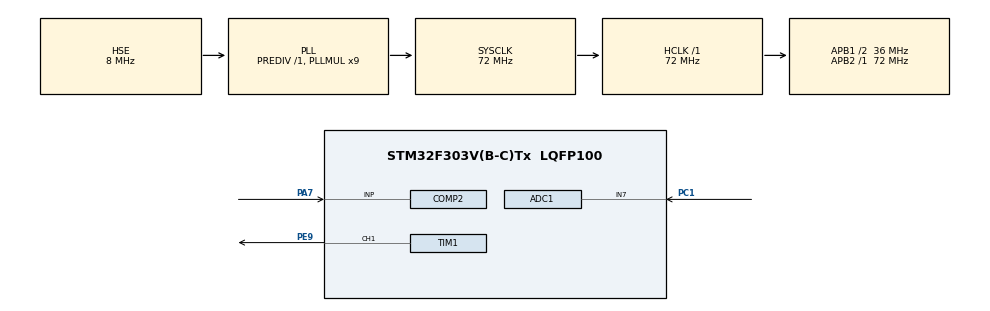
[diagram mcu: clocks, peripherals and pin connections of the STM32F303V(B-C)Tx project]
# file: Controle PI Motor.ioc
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ADC1.Channel-0\#ChannelRegularConversion=ADC_CHANNEL_7
ADC1.ContinuousConvMode=ENABLE
ADC1.DMAContinuousRequests=ENABLE
ADC1.NbrOfConversionFlag=1
ADC1.Offset-0\#ChannelRegularConversion=0
ADC1.OffsetNumber-0\#ChannelRegularConversion=ADC_OFFSET_NONE
ADC1.Rank-0\#ChannelRegularConversion=1
ADC1.SamplingTime-0\#ChannelRegularConversion=ADC_SAMPLETIME_601CYCLES_5
ADC1.master=1
COMP2.Hysteresis=COMP_HYSTERESIS_MEDIUM
COMP2.InvertingInput=COMP_INVERTINGINPUT_3_4VREFINT
COMP2.TriggerMode=COMP_TRIGGERMODE_IT_RISING
Dma.ADC1.0.Direction=DMA_PERIPH_TO_MEMORY
Dma.ADC1.0.Instance=DMA1_Channel1
Dma.ADC1.0.MemDataAlignment=DMA_MDATAALIGN_HALFWORD
Dma.ADC1.0.MemInc=DMA_MINC_ENABLE
Dma.ADC1.0.Mode=DMA_CIRCULAR
Dma.ADC1.0.PeriphDataAlignment=DMA_PDATAALIGN_HALFWORD
Dma.ADC1.0.PeriphInc=DMA_PINC_DISABLE
Dma.ADC1.0.Priority=DMA_PRIORITY_LOW
Dma.Request0=ADC1
Mcu.Family=STM32F3
Mcu.Name=STM32F303V(B-C)Tx
Mcu.Package=LQFP100
NVIC.COMP1_2_3_IRQn=true\:0\:0\:false\:false\:true\:false\:true\:true
NVIC.DMA1_Channel1_IRQn=true\:0\:0\:false\:false\:true\:false\:true\:true
NVIC.PVD_IRQn=true\:0\:0\:false\:false\:true\:true\:true\:true
NVIC.PriorityGroup=NVIC_PRIORITYGROUP_0
NVIC.TIM2_IRQn=true\:0\:0\:false\:false\:true\:true\:true\:true
PA13.Mode=Serial_Wire
PA13.Signal=SYS_JTMS-SWDIO
PA14.Mode=Serial_Wire
PA14.Signal=SYS_JTCK-SWCLK
PA7.Mode=INP
PA7.Signal=COMP2_INP
PC1.Signal=ADCx_IN7
PE9.Signal=S_TIM1_CH1
PF0-OSC_IN.Mode=HSE-External-Oscillator
PF0-OSC_IN.Signal=RCC_OSC_IN
PF1-OSC_OUT.Mode=HSE-External-Oscillator
PF1-OSC_OUT.Signal=RCC_OSC_OUT
ProjectManager.HeapSize=0x200
ProjectManager.StackSize=0x400
ProjectManager.TargetToolchain=STM32CubeIDE
RCC.AHBFreq_Value=72000000
RCC.APB1CLKDivider=RCC_HCLK_DIV2
RCC.APB1Freq_Value=36000000
RCC.APB1TimFreq_Value=72000000
RCC.APB2Freq_Value=72000000
RCC.APB2TimFreq_Value=72000000
RCC.CortexFreq_Value=72000000
RCC.HCLKFreq_Value=72000000
RCC.HSE_VALUE=8000000
RCC.HSI_VALUE=8000000
RCC.LSE_VALUE=32768
RCC.PLLMUL=RCC_PLL_MUL9
RCC.PLLSourceVirtual=RCC_PLLSOURCE_HSE
RCC.SYSCLKFreq_VALUE=72000000
RCC.SYSCLKSourceVirtual=RCC_SYSCLKSOURCE_PLLCLK
RCC.USBFreq_Value=72000000
SH.ADCx_IN7.0=ADC1_IN7,IN7-Single-Ended
SH.S_TIM1_CH1.0=TIM1_CH1,PWM Generation1 CH1
TIM1.Channel-PWM\ Generation1\ CH1=TIM_CHANNEL_1
TIM1.Period=100
TIM1.Prescaler=180-1
TIM2.AutoReloadPreload=TIM_AUTORELOAD_PRELOAD_ENABLE
TIM2.Period=1000-1
TIM2.Prescaler=72-1
VP_COMP2_VS_VREFINT34.Mode=VREFINT_34
VP_TIM2_VS_ClockSourceINT.Mode=Internal
board=STM32F3DISCOVERY

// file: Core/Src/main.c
/* USER CODE BEGIN Header */
/**
  ******************************************************************************
  * @file           : main.c
  * @brief          : Main program body
  ******************************************************************************
  * @attention
  *
  * Copyright (c) 2024 STMicroelectronics.
  * All rights reserved.
  *
  * This software is licensed under terms that can be found in the LICENSE file
  * in the root directory of this software component.
  * If no LICENSE file comes with this software, it is provided AS-IS.
  *
  ******************************************************************************
  */
/* USER CODE END Header */
#include "main.h"

ADC_HandleTypeDef hadc1;
DMA_HandleTypeDef hdma_adc1;

COMP_HandleTypeDef hcomp2;

TIM_HandleTypeDef htim1;
TIM_HandleTypeDef htim2;

/* USER CODE BEGIN PV */
uint32_t leitura, duty, count;
float u[2], ref=0, vel=0, e[2];
int k=1;
float u_max, u_min;
/* USER CODE END PV */

void SystemClock_Config(void);
static void MX_GPIO_Init(void);
static void MX_DMA_Init(void);
static void MX_ADC1_Init(void);
static void MX_TIM1_Init(void);
static void MX_TIM2_Init(void);
static void MX_COMP2_Init(void);

int main(void)
{

  /* MCU Configuration--------------------------------------------------------*/

  /* Reset of all peripherals, Initializes the Flash interface and the Systick. */
  HAL_Init();

  /* Configure the system clock */
  SystemClock_Config();

  /* Initialize all configured peripherals */
  MX_GPIO_Init();
  MX_DMA_Init();
  MX_ADC1_Init();
  MX_TIM1_Init();
  MX_TIM2_Init();
  MX_COMP2_Init();
  /* USER CODE BEGIN 2 */
  HAL_ADC_Start_DMA(&hadc1, &leitura, 1);
  HAL_TIM_PWM_Start(&htim1, TIM_CHANNEL_1);
  HAL_TIM_Base_Start_IT(&htim2);
  HAL_COMP_Start_IT(&hcomp2);

  u[0]=0;
  u[1]=0;
  e[0]=0;
  e[1]=0;
  /* USER CODE END 2 */

  /* Infinite loop */
  while (1)
  {

    /* USER CODE BEGIN 3 */
	  //HAL_GPIO_TogglePin(GPIOE, GPIO_PIN_10);
	  //HAL_Delay(1000);
  }
  /* USER CODE END 3 */
}

void SystemClock_Config(void)
{
  RCC_OscInitTypeDef RCC_OscInitStruct = {0};
  RCC_ClkInitTypeDef RCC_ClkInitStruct = {0};
  RCC_PeriphCLKInitTypeDef PeriphClkInit = {0};

  /** Initializes the RCC Oscillators according to the specified parameters
  * in the RCC_OscInitTypeDef structure.
  */
  RCC_OscInitStruct.OscillatorType = RCC_OSCILLATORTYPE_HSE;
  RCC_OscInitStruct.HSEState = RCC_HSE_ON;
  RCC_OscInitStruct.HSEPredivValue = RCC_HSE_PREDIV_DIV1;
  RCC_OscInitStruct.HSIState = RCC_HSI_ON;
  RCC_OscInitStruct.PLL.PLLState = RCC_PLL_ON;
  RCC_OscInitStruct.PLL.PLLSource = RCC_PLLSOURCE_HSE;
  RCC_OscInitStruct.PLL.PLLMUL = RCC_PLL_MUL9;
  if (HAL_RCC_OscConfig(&RCC_OscInitStruct) != HAL_OK)
  {
    Error_Handler();
  }

  /** Initializes the CPU, AHB and APB buses clocks
  */
  RCC_ClkInitStruct.ClockType = RCC_CLOCKTYPE_HCLK|RCC_CLOCKTYPE_SYSCLK
                              |RCC_CLOCKTYPE_PCLK1|RCC_CLOCKTYPE_PCLK2;
  RCC_ClkInitStruct.SYSCLKSource = RCC_SYSCLKSOURCE_PLLCLK;
  RCC_ClkInitStruct.AHBCLKDivider = RCC_SYSCLK_DIV1;
  RCC_ClkInitStruct.APB1CLKDivider = RCC_HCLK_DIV2;
  RCC_ClkInitStruct.APB2CLKDivider = RCC_HCLK_DIV1;

  if (HAL_RCC_ClockConfig(&RCC_ClkInitStruct, FLASH_LATENCY_2) != HAL_OK)
  {
    Error_Handler();
  }
  PeriphClkInit.PeriphClockSelection = RCC_PERIPHCLK_TIM1|RCC_PERIPHCLK_ADC12;
  PeriphClkInit.Adc12ClockSelection = RCC_ADC12PLLCLK_DIV1;
  PeriphClkInit.Tim1ClockSelection = RCC_TIM1CLK_HCLK;
  if (HAL_RCCEx_PeriphCLKConfig(&PeriphClkInit) != HAL_OK)
  {
    Error_Handler();
  }
}

static void MX_ADC1_Init(void)
{

  ADC_MultiModeTypeDef multimode = {0};
  ADC_ChannelConfTypeDef sConfig = {0};

  /** Common config
  */
  hadc1.Instance = ADC1;
  hadc1.Init.ClockPrescaler = ADC_CLOCK_ASYNC_DIV1;
  hadc1.Init.Resolution = ADC_RESOLUTION_12B;
  hadc1.Init.ScanConvMode = ADC_SCAN_DISABLE;
  hadc1.Init.ContinuousConvMode = ENABLE;
  hadc1.Init.DiscontinuousConvMode = DISABLE;
  hadc1.Init.ExternalTrigConvEdge = ADC_EXTERNALTRIGCONVEDGE_NONE;
  hadc1.Init.ExternalTrigConv = ADC_SOFTWARE_START;
  hadc1.Init.DataAlign = ADC_DATAALIGN_RIGHT;
  hadc1.Init.NbrOfConversion = 1;
  hadc1.Init.DMAContinuousRequests = ENABLE;
  hadc1.Init.EOCSelection = ADC_EOC_SINGLE_CONV;
  hadc1.Init.LowPowerAutoWait = DISABLE;
  hadc1.Init.Overrun = ADC_OVR_DATA_OVERWRITTEN;
  if (HAL_ADC_Init(&hadc1) != HAL_OK)
  {
    Error_Handler();
  }

  /** Configure the ADC multi-mode
  */
  multimode.Mode = ADC_MODE_INDEPENDENT;
  if (HAL_ADCEx_MultiModeConfigChannel(&hadc1, &multimode) != HAL_OK)
  {
    Error_Handler();
  }

  /** Configure Regular Channel
  */
  sConfig.Channel = ADC_CHANNEL_7;
  sConfig.Rank = ADC_REGULAR_RANK_1;
  sConfig.SingleDiff = ADC_SINGLE_ENDED;
  sConfig.SamplingTime = ADC_SAMPLETIME_601CYCLES_5;
  sConfig.OffsetNumber = ADC_OFFSET_NONE;
  sConfig.Offset = 0;
  if (HAL_ADC_ConfigChannel(&hadc1, &sConfig) != HAL_OK)
  {
    Error_Handler();
  }

}

static void MX_COMP2_Init(void)
{

  hcomp2.Instance = COMP2;
  hcomp2.Init.InvertingInput = COMP_INVERTINGINPUT_3_4VREFINT;
  hcomp2.Init.NonInvertingInput = COMP_NONINVERTINGINPUT_IO1;
  hcomp2.Init.Output = COMP_OUTPUT_NONE;
  hcomp2.Init.OutputPol = COMP_OUTPUTPOL_NONINVERTED;
  hcomp2.Init.Hysteresis = COMP_HYSTERESIS_MEDIUM;
  hcomp2.Init.BlankingSrce = COMP_BLANKINGSRCE_NONE;
  hcomp2.Init.Mode = COMP_MODE_HIGHSPEED;
  hcomp2.Init.WindowMode = COMP_WINDOWMODE_DISABLE;
  hcomp2.Init.TriggerMode = COMP_TRIGGERMODE_IT_RISING;
  if (HAL_COMP_Init(&hcomp2) != HAL_OK)
  {
    Error_Handler();
  }

}

static void MX_TIM1_Init(void)
{

  TIM_MasterConfigTypeDef sMasterConfig = {0};
  TIM_OC_InitTypeDef sConfigOC = {0};
  TIM_BreakDeadTimeConfigTypeDef sBreakDeadTimeConfig = {0};

  htim1.Instance = TIM1;
  htim1.Init.Prescaler = 180-1;
  htim1.Init.CounterMode = TIM_COUNTERMODE_UP;
  htim1.Init.Period = 100;
  htim1.Init.ClockDivision = TIM_CLOCKDIVISION_DIV1;
  htim1.Init.RepetitionCounter = 0;
  htim1.Init.AutoReloadPreload = TIM_AUTORELOAD_PRELOAD_DISABLE;
  if (HAL_TIM_PWM_Init(&htim1) != HAL_OK)
  {
    Error_Handler();
  }
  sMasterConfig.MasterOutputTrigger = TIM_TRGO_RESET;
  sMasterConfig.MasterOutputTrigger2 = TIM_TRGO2_RESET;
  sMasterConfig.MasterSlaveMode = TIM_MASTERSLAVEMODE_DISABLE;
  if (HAL_TIMEx_MasterConfigSynchronization(&htim1, &sMasterConfig) != HAL_OK)
  {
    Error_Handler();
  }
  sConfigOC.OCMode = TIM_OCMODE_PWM1;
  sConfigOC.Pulse = 0;
  sConfigOC.OCPolarity = TIM_OCPOLARITY_HIGH;
  sConfigOC.OCNPolarity = TIM_OCNPOLARITY_HIGH;
  sConfigOC.OCFastMode = TIM_OCFAST_DISABLE;
  sConfigOC.OCIdleState = TIM_OCIDLESTATE_RESET;
  sConfigOC.OCNIdleState = TIM_OCNIDLESTATE_RESET;
  if (HAL_TIM_PWM_ConfigChannel(&htim1, &sConfigOC, TIM_CHANNEL_1) != HAL_OK)
  {
    Error_Handler();
  }
  sBreakDeadTimeConfig.OffStateRunMode = TIM_OSSR_DISABLE;
  sBreakDeadTimeConfig.OffStateIDLEMode = TIM_OSSI_DISABLE;
  sBreakDeadTimeConfig.LockLevel = TIM_LOCKLEVEL_OFF;
  sBreakDeadTimeConfig.DeadTime = 0;
  sBreakDeadTimeConfig.BreakState = TIM_BREAK_DISABLE;
  sBreakDeadTimeConfig.BreakPolarity = TIM_BREAKPOLARITY_HIGH;
  sBreakDeadTimeConfig.BreakFilter = 0;
  sBreakDeadTimeConfig.Break2State = TIM_BREAK2_DISABLE;
  sBreakDeadTimeConfig.Break2Polarity = TIM_BREAK2POLARITY_HIGH;
  sBreakDeadTimeConfig.Break2Filter = 0;
  sBreakDeadTimeConfig.AutomaticOutput = TIM_AUTOMATICOUTPUT_DISABLE;
  if (HAL_TIMEx_ConfigBreakDeadTime(&htim1, &sBreakDeadTimeConfig) != HAL_OK)
  {
    Error_Handler();
  }
  HAL_TIM_MspPostInit(&htim1);

}

static void MX_TIM2_Init(void)
{

  TIM_ClockConfigTypeDef sClockSourceConfig = {0};
  TIM_MasterConfigTypeDef sMasterConfig = {0};

  htim2.Instance = TIM2;
  htim2.Init.Prescaler = 72-1;
  htim2.Init.CounterMode = TIM_COUNTERMODE_UP;
  htim2.Init.Period = 1000-1;
  htim2.Init.ClockDivision = TIM_CLOCKDIVISION_DIV1;
  htim2.Init.AutoReloadPreload = TIM_AUTORELOAD_PRELOAD_ENABLE;
  if (HAL_TIM_Base_Init(&htim2) != HAL_OK)
  {
    Error_Handler();
  }
  sClockSourceConfig.ClockSource = TIM_CLOCKSOURCE_INTERNAL;
  if (HAL_TIM_ConfigClockSource(&htim2, &sClockSourceConfig) != HAL_OK)
  {
    Error_Handler();
  }
  sMasterConfig.MasterOutputTrigger = TIM_TRGO_RESET;
  sMasterConfig.MasterSlaveMode = TIM_MASTERSLAVEMODE_DISABLE;
  if (HAL_TIMEx_MasterConfigSynchronization(&htim2, &sMasterConfig) != HAL_OK)
  {
    Error_Handler();
  }

}

static void MX_DMA_Init(void)
{

  /* DMA controller clock enable */
  __HAL_RCC_DMA1_CLK_ENABLE();

  /* DMA interrupt init */
  /* DMA1_Channel1_IRQn interrupt configuration */
  HAL_NVIC_SetPriority(DMA1_Channel1_IRQn, 0, 0);
  HAL_NVIC_EnableIRQ(DMA1_Channel1_IRQn);

}

static void MX_GPIO_Init(void)
{

  /* GPIO Ports Clock Enable */
  __HAL_RCC_GPIOF_CLK_ENABLE();
  __HAL_RCC_GPIOC_CLK_ENABLE();
  __HAL_RCC_GPIOA_CLK_ENABLE();
  __HAL_RCC_GPIOE_CLK_ENABLE();

}

void Error_Handler(void)
{
  __disable_irq();
  while (1)
  {
  }
}
